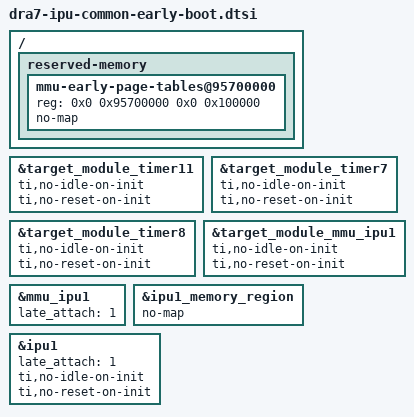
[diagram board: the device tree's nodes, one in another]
// SPDX-License-Identifier: GPL-2.0
/*
 * Copyright (C) 2019 Texas Instruments Incorporated - http://www.ti.com/
 *
 * Common dtsi file that needs to be included in corresponding TI DRA7xx
 * and AM57xx board dts files that have the IPU1 _and_ IPU2 remote processors
 * booted early from TI U-Boot/SPL.
 */

/ {
	reserved-memory {
		mmu-early-page-tables@95700000 {
			/* address need to match the usage within U-Boot */
			reg = <0x0 0x95700000 0x0 0x100000>;
			no-map;
			status = "okay";
		};
	};
};

/* IPU1 */
&target_module_timer11 {
	ti,no-idle-on-init;
	ti,no-reset-on-init;
};

&target_module_timer7 {
	ti,no-idle-on-init;
	ti,no-reset-on-init;
};

&target_module_timer8 {
	ti,no-idle-on-init;
	ti,no-reset-on-init;
};

&target_module_mmu_ipu1{
	/* Delete the clocks and resets as they are not registered at init time */
	/delete-property/ clocks;
	/delete-property/ clock-names;
	/delete-property/ resets;
	/delete-property/ reset-names;
	ti,no-idle-on-init;
	ti,no-reset-on-init;
};

&mmu_ipu1 {
	late_attach = <1>;
};


&ipu1_memory_region {
	/delete-property/ reusable;
	no-map;
};

&ipu1 {
	/* Delete the clocks and resets as they are not registered at init time */
	/delete-property/ clocks;
	/delete-property/ resets;
	late_attach = <1>;
	ti,no-idle-on-init;
	ti,no-reset-on-init;
};
